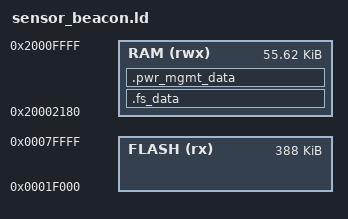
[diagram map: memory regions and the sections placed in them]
/* Linker script for Nordic Semiconductor nRF5x devices
 *
 * Version: Sourcery G++ 4.5-1
 * Support: https://support.codesourcery.com/GNUToolchain/
 *
 * Copyright (c) 2007, 2008, 2009, 2010 CodeSourcery, Inc.
 *
 * The authors hereby grant permission to use, copy, modify, distribute,
 * and license this software and its documentation for any purpose, provided
 * that existing copyright notices are retained in all copies and that this
 * notice is included verbatim in any distributions.  No written agreement,
 * license, or royalty fee is required for any of the authorized uses.
 * Modifications to this software may be copyrighted by their authors
 * and need not follow the licensing terms described here, provided that
 * the new terms are clearly indicated on the first page of each file where
 * they apply.
 */

SEARCH_DIR(.)
GROUP(-lgcc -lc -lnosys)

MEMORY
{
  FLASH (rx) : ORIGIN = 0x1f000, LENGTH = 0x61000
  RAM (rwx) :  ORIGIN = 0x20002180, LENGTH = 0xde80
}

SECTIONS
{
  .fs_data :
  {
    PROVIDE(__start_fs_data = .);
    KEEP(*(.fs_data))
    PROVIDE(__stop_fs_data = .);
  } > RAM
  .pwr_mgmt_data :
  {
    PROVIDE(__start_pwr_mgmt_data = .);
    KEEP(*(.pwr_mgmt_data))
    PROVIDE(__stop_pwr_mgmt_data = .);
  } > RAM
} INSERT AFTER .data;

INCLUDE "nrf5x_common.ld"
